# AT32F457xx_v2 register map
Vendor: Keil; Series: AT32F457; File version: 1.0
CPU: CM4 r0p1, little endian, no MPU, FPU, 4 interrupt priority bits
Registers are 32-bit, read-write, reset 0x0 unless marked. A register's access mark holds for its fields unless they carry their own. Offsets are from the block's base; [hi:lo] are bit positions; {n}, {i} and the like mark numbered series.

## AES — AES Controller
Base 0x50060000
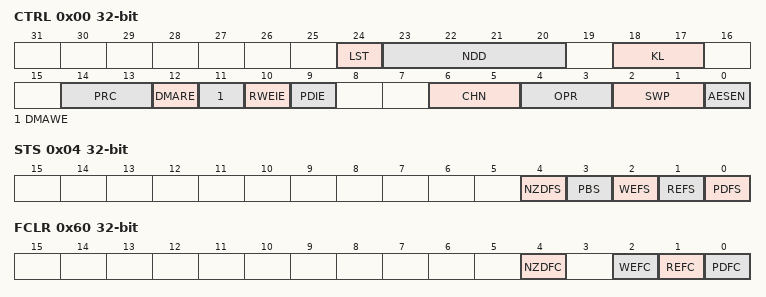
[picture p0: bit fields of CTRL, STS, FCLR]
0x00 CTRL — Control register
  [24] LST — Processing last block
  [23:20] NDD — Number of dummy data
  [18:17] KL — Key length
  [14:13] PRC — Processing stage
  [12] DMARE — DMA read channel enable
  [11] DMAWE — DMA write channel enable
  [10] RWEIE — Read and write error interrupt enable
  [9] PDIE — Processing done interrupt enable
  [6:5] CHN — Chaining mode
  [4:3] OPR — Encrypt/Decrypt mode
  [2:1] SWP — Data swap
  [0] AESEN — AES enable
0x04 STS ro — Status register
  [4] NZDFS — Non-zero dummy data processing flag status
  [3] PBS — Busy status
  [2] WEFS — Write error status
  [1] REFS — Read error status
  [0] PDFS — Processing done status
0x08 IDT wo — Input data port
0x0C ODT ro — Output data port
{0x10+4i} KEY{i} (i=0..3) — Key W{i} register
{0x20+4i} IV{i} (i=0..3) — Initial victor W{i} register
{0x20+4i} KEY{i} (i=4..7) — Key W{i} register
{0x40+4i} SI{i} (i=0..7) — Suspend information W{i} register
0x60 FCLR wo — Flag clear register
  [4] NZDFC — Non-zero dummy data processed flag clear
  [2] WEFC — Write error flag clear
  [1] REFC — Read error flag clear
  [0] PDFC — processing done flag clear

## TRNG — True Random Number Generator
Base 0x50060800
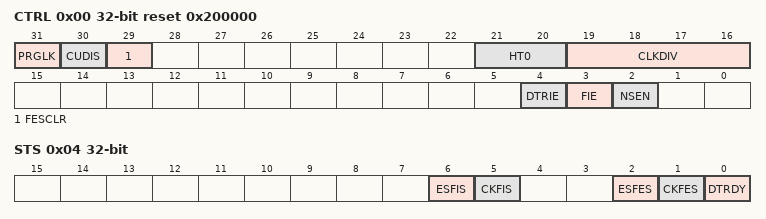
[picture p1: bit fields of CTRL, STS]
0x00 CTRL reset 0x200000 — Control register
  [31] PRGLK — Programing register lock
  [30] CUDIS — Conditioning unit and output buffer disable
  [29] FESCLR — Clock fail event and entropy source fail event status clear
  [21:20] HT0 — Health test parameter 0
  [19:16] CLKDIV — Noise source clock divider factor
  [4] DTRIE — Data port ready interrupt enable
  [3] FIE — Fail interrupt enable
  [2] NSEN — Noise source enable
0x04 STS — Status register
  [6] ESFIS — Entropy source fail interrupt status
  [5] CKFIS — Clock fail interrupt status
  [2] ESFES — Entropy source fail event status
  [1] CKFES — Clock fail event status
  [0] DTRDY — Data port ready
0x08 DT ro — Data port
0x0C HTCTRL reset 0x42CE8 — Health test controller
  [19:0] HT1 — Health test parameter 1

## ETHERNET_MMC — Ethernet: MAC management counters
Base 0x40028100
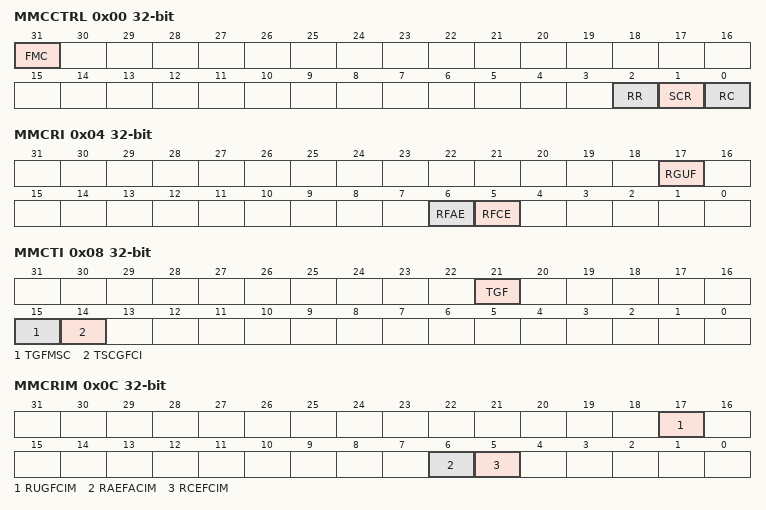
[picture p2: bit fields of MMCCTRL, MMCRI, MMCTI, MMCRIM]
0x00 MMCCTRL — Ethernet MMC control register
  [31] FMC — Freeze MMC counter
  [2] RR — Reset on read
  [1] SCR — Stop counter rollover
  [0] RC — Reset counter
0x04 MMCRI — Ethernet MMC receive interrupt register
  [17] RGUF — Received good unicast frames
  [6] RFAE — Received frames alignment error
  [5] RFCE — Received frames CRC error
0x08 MMCTI — Ethernet MMC transmit interrupt register
  [21] TGF — Transmitted good frames
  [15] TGFMSC — Transmit good frames more single collision
  [14] TSCGFCI — Transmit single collision good frame counter interrupt
0x0C MMCRIM — Ethernet MMC receive interrupt mask register
  [17] RUGFCIM — Received unicast good frame counter interrupt mask
  [6] RAEFACIM — Received alignment error frame alignment counter interrupt mask
  [5] RCEFCIM — Received CRC error frame counter interrupt mask
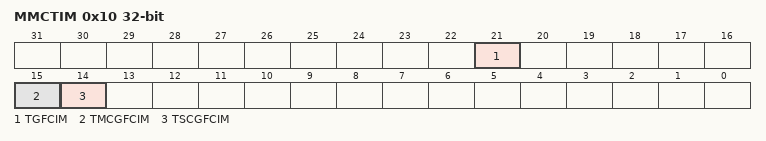
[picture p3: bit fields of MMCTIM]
0x10 MMCTIM — Ethernet MMC transmit interrupt mask register
  [21] TGFCIM — Transmitted good frame counter interrupt mask
  [15] TMCGFCIM — Transmit multiple collision good frame counter interrupt mask
  [14] TSCGFCIM — Transmit single collision good frame counter interrupt mask
0x4C MMCTFSCC ro — Ethernet MMC transmitted good frames after a single collision counter
  [31:0] TGFSCC — Transmitted good frames single collision counter
0x50 MMCTFMSCC ro — Ethernet MMC transmitted good frames after more than a single collision
  [31:0] TGFMSCC — Transmitted good frame more single collision counter
0x68 MMCTFCNT ro — Ethernet MMC transmitted good frames counter register
  [31:0] TGFC — Transmitted good frames counter
0x94 MMCRFCECNT ro — Ethernet MMC received frames with CRC error counter register
  [31:0] RFCEC — Received frames CRC error counter
0x98 MMCRFAECNT ro — Ethernet MMC received frames with alignment error counter register
  [31:0] RFAEC — Received frames alignment error counter
0xC4 MMCRGUFCNT ro — MMC received good unicast frames counter register
  [31:0] RGUFC — Received good unicast frames counter

## ETHERNET_PTP — Ethernet: Precision time protocol
Base 0x40028700
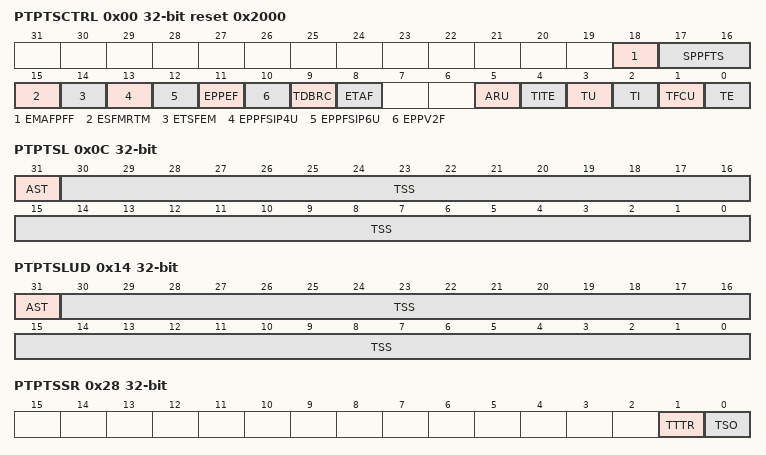
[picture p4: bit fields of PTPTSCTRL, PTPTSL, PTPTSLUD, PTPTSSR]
0x00 PTPTSCTRL reset 0x2000 — Ethernet PTP time stamp control register
  [18] EMAFPFF — Enable MAC address for PTP frame filtering
  [17:16] SPPFTS — Select PTP packet for taking snapshot
  [15] ESFMRTM — Enable snapshot for message relevant to master
  [14] ETSFEM — Enable timestamp snapshot for event message
  [13] EPPFSIP4U — Enable processing of PTP frames sent over IPv4-UDP
  [12] EPPFSIP6U — Enable processing of PTP frames sent over IPv6-UDP
  [11] EPPEF — Enable processing of PTP over EMAC frames
  [10] EPPV2F — Enable PTP packet processing for version2 format
  [9] TDBRC — Timestamp digital or binary rollover control
  [8] ETAF — Enable timestamp for all frames
  [5] ARU — Addend register update
  [4] TITE — Timestamp interrupt trigger enable
  [3] TU — Timestamp update
  [2] TI — Timestamp initialize
  [1] TFCU — Timestamp fine or coarse update
  [0] TE — Timestamp enable
0x04 PTPSSINC — Ethernet PTP subsecond increment register
  [7:0] SSIV — Sub-second increment value
0x08 PTPTSH ro — Ethernet PTP time stamp high register
  [31:0] TS — Timestamp second
0x0C PTPTSL ro — Ethernet PTP time stamp low register
  [31] AST — Add or subtract time
  [30:0] TSS — Timestamp subseconds
0x10 PTPTSHUD — Ethernet PTP time stamp high update register
  [31:0] TS — Timestamp second
0x14 PTPTSLUD — Ethernet PTP time stamp low update register
  [31] AST — Add or subtract time
  [30:0] TSS — Timestamp subseconds
0x18 PTPTSAD — Ethernet PTP time stamp addend register
  [31:0] TAR — Timestamp addend register
0x1C PTPTTH — Ethernet PTP target time high register
  [31:0] TTSR — Target time seconds register
0x20 PTPTTL — Ethernet PTP target time low register
  [31:0] TTLR — Target timestamp low register
0x28 PTPTSSR ro — Ethernet PTP time stamp status register
  [1] TTTR — Timestamp target time reached
  [0] TSO — Timestamp second overflow
0x2C PTPPPSCR ro — Ethernet PTP PPS control register
  [3:0] POFC — PPS Output frequency control

## Notices in the file
Copyright (C) 2012-2014 ARM Limited. All rights reserved.
Purpose: System Viewer Description (SVD) Example (Schema Version 1.1)
This is a description of a none-existent and incomplete device
for demonstration purposes only.
Redistribution and use in source and binary forms, with or without
modification, are permitted provided that the following conditions are met:
- Redistributions of source code must retain the above copyright
notice, this list of conditions and the following disclaimer.
- Redistributions in binary form must reproduce the above copyright
notice, this list of conditions and the following disclaimer in the
documentation and/or other materials provided with the distribution.
- Neither the name of ARM nor the names of its contributors may be used
to endorse or promote products derived from this software without
specific prior written permission.
THIS SOFTWARE IS PROVIDED BY THE COPYRIGHT HOLDERS AND CONTRIBUTORS "AS IS"
AND ANY EXPRESS OR IMPLIED WARRANTIES, INCLUDING, BUT NOT LIMITED TO, THE
IMPLIED WARRANTIES OF MERCHANTABILITY AND FITNESS FOR A PARTICULAR PURPOSE
ARE DISCLAIMED. IN NO EVENT SHALL COPYRIGHT HOLDERS AND CONTRIBUTORS BE
LIABLE FOR ANY DIRECT, INDIRECT, INCIDENTAL, SPECIAL, EXEMPLARY, OR
CONSEQUENTIAL DAMAGES (INCLUDING, BUT NOT LIMITED TO, PROCUREMENT OF
SUBSTITUTE GOODS OR SERVICES; LOSS OF USE, DATA, OR PROFITS; OR BUSINESS
INTERRUPTION) HOWEVER CAUSED AND ON ANY THEORY OF LIABILITY, WHETHER IN
CONTRACT, STRICT LIABILITY, OR TORT (INCLUDING NEGLIGENCE OR OTHERWISE)
ARISING IN ANY WAY OUT OF THE USE OF THIS SOFTWARE, EVEN IF ADVISED OF THE
POSSIBILITY OF SUCH DAMAGE.
